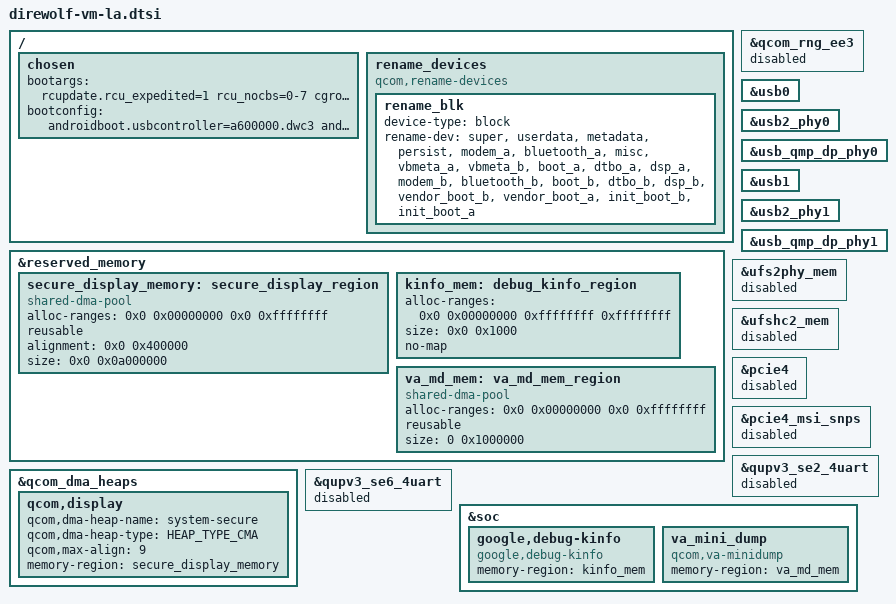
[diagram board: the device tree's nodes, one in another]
// SPDX-License-Identifier: BSD-3-Clause
/*
 * Copyright (c) 2024-2025 Qualcomm Innovation Center, Inc. All rights reserved.
 */

#include <dt-bindings/mailbox/qcom-ipcc.h>

&reserved_memory {
	secure_display_memory: secure_display_region {
		compatible = "shared-dma-pool";
		alloc-ranges = <0x0 0x00000000 0x0 0xffffffff>;
		reusable;
		alignment = <0x0 0x400000>;
		size = <0x0 0x0a000000>;
	};

	kinfo_mem: debug_kinfo_region {
		alloc-ranges = <0x0 0x00000000 0xffffffff 0xffffffff>;
		size = <0x0 0x1000>;
		no-map;
	};

	va_md_mem: va_md_mem_region {
		compatible = "shared-dma-pool";
		alloc-ranges = <0x0 0x00000000 0x0 0xffffffff>;
		reusable;
		size = <0 0x1000000>;
	};
};

&qcom_dma_heaps {
	qcom,display {
		qcom,dma-heap-name = "system-secure";
		qcom,dma-heap-type = <HEAP_TYPE_CMA>;
		qcom,max-align = <9>;
		memory-region = <&secure_display_memory>;
	};
};

&qcom_rng_ee3 {
	status = "disabled";
};

&usb0 {
	status = "okay";
};

&usb2_phy0 {
	status = "okay";
};

&usb_qmp_dp_phy0 {
	status = "okay";
};

&usb1 {
	status = "okay";
};

&usb2_phy1 {
	status = "okay";
};

&usb_qmp_dp_phy1 {
	status = "okay";
};

&ufs2phy_mem {
	status = "disabled";
};

&ufshc2_mem {
	status = "disabled";
};

&pcie4 {
	/delete-property/ iommu-map;
	status = "disabled";
};

&pcie4_msi_snps {
	status = "disabled";
};

&qupv3_se2_4uart {
	status = "disabled";
};

&qupv3_se6_4uart {
	status = "disabled";
};

/ {
	chosen {
		bootargs = "rcupdate.rcu_expedited=1 rcu_nocbs=0-7 cgroup.memory=nokmem,nosocket kpti=0 qcom_dma_heaps.enable_bitstream_contig_heap=y ufshcd-core.use_mcq_mode=n arm64.nopauth kasan=off msm_show_resume_irq.debug_mask=1 ";
		bootconfig = " androidboot.usbcontroller=a600000.dwc3 androidboot.fstab_suffix=gen4.qcom androidboot.dtbo_idx=0";
	};

	rename_devices: rename_devices {
		compatible = "qcom,rename-devices";
		rename_blk: rename_blk {
			device-type = "block";
			rename-dev = "super", "userdata", "metadata",
					"persist", "modem_a","bluetooth_a",
					"misc", "vbmeta_a", "vbmeta_b",
					"boot_a", "dtbo_a","dsp_a",
					"modem_b", "bluetooth_b", "boot_b",
					"dtbo_b", "dsp_b", "vendor_boot_b",
					"vendor_boot_a", "init_boot_b", "init_boot_a";
		};
	};
};

&soc {
	google,debug-kinfo {
		compatible = "google,debug-kinfo";
		memory-region = <&kinfo_mem>;
	};

	va_mini_dump {
		compatible = "qcom,va-minidump";
		memory-region = <&va_md_mem>;
	};
};

